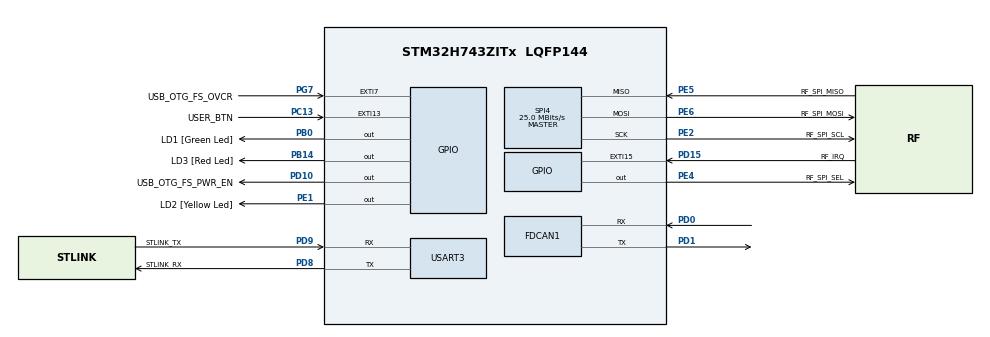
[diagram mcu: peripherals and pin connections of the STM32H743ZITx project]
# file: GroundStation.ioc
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Dma.Request0=USART3_RX
Dma.Request1=USART3_TX
Dma.USART3_RX.0.Direction=DMA_PERIPH_TO_MEMORY
Dma.USART3_RX.0.EventEnable=DISABLE
Dma.USART3_RX.0.FIFOMode=DMA_FIFOMODE_DISABLE
Dma.USART3_RX.0.Instance=DMA1_Stream0
Dma.USART3_RX.0.MemDataAlignment=DMA_MDATAALIGN_BYTE
Dma.USART3_RX.0.MemInc=DMA_MINC_ENABLE
Dma.USART3_RX.0.Mode=DMA_NORMAL
Dma.USART3_RX.0.PeriphDataAlignment=DMA_PDATAALIGN_BYTE
Dma.USART3_RX.0.PeriphInc=DMA_PINC_DISABLE
Dma.USART3_RX.0.Polarity=HAL_DMAMUX_REQ_GEN_RISING
Dma.USART3_RX.0.Priority=DMA_PRIORITY_LOW
Dma.USART3_RX.0.RequestNumber=1
Dma.USART3_RX.0.SignalID=NONE
Dma.USART3_RX.0.SyncEnable=DISABLE
Dma.USART3_RX.0.SyncPolarity=HAL_DMAMUX_SYNC_NO_EVENT
Dma.USART3_RX.0.SyncRequestNumber=1
Dma.USART3_RX.0.SyncSignalID=NONE
Dma.USART3_TX.1.Direction=DMA_MEMORY_TO_PERIPH
Dma.USART3_TX.1.EventEnable=DISABLE
Dma.USART3_TX.1.FIFOMode=DMA_FIFOMODE_DISABLE
Dma.USART3_TX.1.Instance=DMA1_Stream1
Dma.USART3_TX.1.MemDataAlignment=DMA_MDATAALIGN_BYTE
Dma.USART3_TX.1.MemInc=DMA_MINC_ENABLE
Dma.USART3_TX.1.Mode=DMA_NORMAL
Dma.USART3_TX.1.PeriphDataAlignment=DMA_PDATAALIGN_BYTE
Dma.USART3_TX.1.PeriphInc=DMA_PINC_DISABLE
Dma.USART3_TX.1.Polarity=HAL_DMAMUX_REQ_GEN_RISING
Dma.USART3_TX.1.Priority=DMA_PRIORITY_LOW
Dma.USART3_TX.1.RequestNumber=1
Dma.USART3_TX.1.SignalID=NONE
Dma.USART3_TX.1.SyncEnable=DISABLE
Dma.USART3_TX.1.SyncPolarity=HAL_DMAMUX_SYNC_NO_EVENT
Dma.USART3_TX.1.SyncRequestNumber=1
Dma.USART3_TX.1.SyncSignalID=NONE
FDCAN1.CalculateBaudRateNominal=1000000
FDCAN1.CalculateTimeBitNominal=1000
FDCAN1.CalculateTimeQuantumNominal=20.0
FDCAN1.DataPrescaler=25
FDCAN1.DataTimeSeg1=2
FDCAN1.ExtFiltersNbr=1
FDCAN1.NominalPrescaler=1
FDCAN1.NominalSyncJumpWidth=13
FDCAN1.NominalTimeSeg1=40
FDCAN1.NominalTimeSeg2=9
FDCAN1.RxFifo0ElmtsNbr=16
FDCAN1.TxFifoQueueElmtsNbr=16
Mcu.Family=STM32H7
Mcu.Name=STM32H743ZITx
Mcu.Package=LQFP144
NVIC.DMA1_Stream0_IRQn=true\:5\:0\:true\:false\:true\:false\:true\:true
NVIC.DMA1_Stream1_IRQn=true\:5\:0\:true\:false\:true\:false\:true\:true
NVIC.EXTI15_10_IRQn=true\:5\:0\:true\:false\:false\:true\:true\:true
NVIC.FDCAN1_IT0_IRQn=true\:5\:0\:true\:false\:true\:true\:true\:true
NVIC.FDCAN1_IT1_IRQn=true\:5\:0\:true\:false\:true\:true\:true\:true
NVIC.PriorityGroup=NVIC_PRIORITYGROUP_4
NVIC.TIM1_UP_IRQn=true\:15\:0\:false\:false\:true\:false\:true\:true
NVIC.TimeBase=TIM1_UP_IRQn
NVIC.TimeBaseIP=TIM1
NVIC.USART3_IRQn=true\:5\:0\:true\:false\:true\:true\:true\:true
PA1.Signal=ETH_REF_CLK
PA11.Signal=USB_OTG_FS_DM
PA12.Signal=USB_OTG_FS_DP
PA2.Signal=ETH_MDIO
PA7.Signal=ETH_CRS_DV
PA8.Signal=USB_OTG_FS_SOF
PA9.Signal=USB_OTG_FS_VBUS
PB0.GPIO_Label=LD1 [Green Led]
PB0.Signal=GPIO_Output
PB13.Signal=ETH_TXD1
PB14.GPIO_Label=LD3 [Red Led]
PB14.Signal=GPIO_Output
PC1.Signal=ETH_MDC
PC13.GPIO_Label=USER_BTN
PC13.Signal=GPXTI13
PC14-OSC32_IN\ (OSC32_IN).Mode=LSE-External-Oscillator
PC14-OSC32_IN\ (OSC32_IN).Signal=RCC_OSC32_IN
PC15-OSC32_OUT\ (OSC32_OUT).Mode=LSE-External-Oscillator
PC15-OSC32_OUT\ (OSC32_OUT).Signal=RCC_OSC32_OUT
PC4.Signal=ETH_RXD0
PC5.Signal=ETH_RXD1
PD0.Mode=FDCAN_Activate
PD0.Signal=FDCAN1_RX
PD1.Mode=FDCAN_Activate
PD1.Signal=FDCAN1_TX
PD10.GPIO_Label=USB_OTG_FS_PWR_EN
PD10.Signal=GPIO_Output
PD15.GPIO_Label=RF_IRQ
PD15.Signal=GPXTI15
PD8.GPIO_Label=STLINK_RX
PD8.Mode=Asynchronous
PD8.Signal=USART3_TX
PD9.GPIO_Label=STLINK_TX
PD9.Mode=Asynchronous
PD9.Signal=USART3_RX
PE1.GPIO_Label=LD2 [Yellow Led]
PE1.Signal=GPIO_Output
PE2.GPIO_Label=RF_SPI_SCL
PE2.Mode=Full_Duplex_Master
PE2.Signal=SPI4_SCK
PE4.GPIO_Label=RF_SPI_SEL
PE4.Signal=GPIO_Output
PE5.GPIO_Label=RF_SPI_MISO
PE5.Mode=Full_Duplex_Master
PE5.Signal=SPI4_MISO
PE6.GPIO_Label=RF_SPI_MOSI
PE6.Mode=Full_Duplex_Master
PE6.Signal=SPI4_MOSI
PG11.Signal=ETH_TX_EN
PG13.Signal=ETH_TXD0
PG7.GPIO_Label=USB_OTG_FS_OVCR
PG7.Signal=GPXTI7
PH0-OSC_IN\ (PH0).Mode=HSE-External-Oscillator
PH0-OSC_IN\ (PH0).Signal=RCC_OSC_IN
PH1-OSC_OUT\ (PH1).Mode=HSE-External-Oscillator
PH1-OSC_OUT\ (PH1).Signal=RCC_OSC_OUT
ProjectManager.HeapSize=0x200
ProjectManager.StackSize=0x400
ProjectManager.TargetToolchain=CMake
RCC.ADCFreq_Value=75000000
RCC.APB1Freq_Value=64000000
RCC.APB2Freq_Value=64000000
RCC.APB3Freq_Value=64000000
RCC.APB4Freq_Value=64000000
RCC.CortexFreq_Value=64000000
RCC.DIVM1=1
RCC.DIVM2=1
RCC.DIVN1=18
RCC.DIVN2=18
RCC.DIVQ1=3
RCC.DIVQ2=3
RCC.HCLKFreq_Value=64000000
RCC.HSE_VALUE=8000000
RCC.PLL2FRACN=6144
RCC.PLLFRACN=6144
RCC.PLLSourceVirtual=RCC_PLLSOURCE_HSE
RCC.PWR_Regulator_Voltage_Scale=PWR_REGULATOR_VOLTAGE_SCALE2
RCC.SYSCLKFreq_VALUE=64000000
RCC.Spi45ClockSelection=RCC_SPI45CLKSOURCE_PLL2
RCC.USBFreq_Value=50000000
SPI4.CalculateBaudRate=25.0 MBits/s
SPI4.DataSize=SPI_DATASIZE_8BIT
SPI4.Direction=SPI_DIRECTION_2LINES
SPI4.Mode=SPI_MODE_MASTER
SPI4.VirtualType=VM_MASTER
USART3.VirtualMode-Asynchronous=VM_ASYNC
VP_CRC_VS_CRC.Mode=CRC_Activate
VP_MEMORYMAP_VS_MEMORYMAP.Mode=CurAppReg
VP_SYS_VS_tim1.Mode=TIM1
board=NUCLEO-H743ZI2

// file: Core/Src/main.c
/* USER CODE BEGIN Header */
/**
  ******************************************************************************
  * @file           : main.c
  * @brief          : Main program body
  ******************************************************************************
  * @attention
  *
  * Copyright (c) 2024 STMicroelectronics.
  * All rights reserved.
  *
  * This software is licensed under terms that can be found in the LICENSE file
  * in the root directory of this software component.
  * If no LICENSE file comes with this software, it is provided AS-IS.
  *
  ******************************************************************************
  */
/* USER CODE END Header */
#include "main.h"

CRC_HandleTypeDef hcrc;

FDCAN_HandleTypeDef hfdcan1;

SPI_HandleTypeDef hspi4;

UART_HandleTypeDef huart3;
DMA_HandleTypeDef hdma_usart3_rx;
DMA_HandleTypeDef hdma_usart3_tx;

void SystemClock_Config(void);
static void MX_GPIO_Init(void);
static void MX_DMA_Init(void);
static void MX_SPI4_Init(void);
static void MX_USART3_UART_Init(void);
static void MX_CRC_Init(void);
static void MX_FDCAN1_Init(void);

/* USER CODE BEGIN 0 */
void app_main(void);
/* USER CODE END 0 */

int main(void)
{

  /* MCU Configuration--------------------------------------------------------*/

  /* Reset of all peripherals, Initializes the Flash interface and the Systick. */
  HAL_Init();

  /* Configure the system clock */
  SystemClock_Config();

  /* Initialize all configured peripherals */
  MX_GPIO_Init();
  MX_DMA_Init();
  MX_SPI4_Init();
  MX_USART3_UART_Init();
  MX_CRC_Init();
  MX_FDCAN1_Init();
  /* USER CODE BEGIN 2 */
    app_main();
  /* USER CODE END 2 */

  /* Infinite loop */
  while (1)
  {

  }
}

void SystemClock_Config(void)
{
  RCC_OscInitTypeDef RCC_OscInitStruct = {0};
  RCC_ClkInitTypeDef RCC_ClkInitStruct = {0};

  /** Supply configuration update enable
  */
  HAL_PWREx_ConfigSupply(PWR_LDO_SUPPLY);

  /** Configure the main internal regulator output voltage
  */
  __HAL_PWR_VOLTAGESCALING_CONFIG(PWR_REGULATOR_VOLTAGE_SCALE2);

  while(!__HAL_PWR_GET_FLAG(PWR_FLAG_VOSRDY)) {}

  /** Initializes the RCC Oscillators according to the specified parameters
  * in the RCC_OscInitTypeDef structure.
  */
  RCC_OscInitStruct.OscillatorType = RCC_OSCILLATORTYPE_HSI|RCC_OSCILLATORTYPE_HSE;
  RCC_OscInitStruct.HSEState = RCC_HSE_ON;
  RCC_OscInitStruct.HSIState = RCC_HSI_DIV1;
  RCC_OscInitStruct.HSICalibrationValue = RCC_HSICALIBRATION_DEFAULT;
  RCC_OscInitStruct.PLL.PLLState = RCC_PLL_ON;
  RCC_OscInitStruct.PLL.PLLSource = RCC_PLLSOURCE_HSE;
  RCC_OscInitStruct.PLL.PLLM = 1;
  RCC_OscInitStruct.PLL.PLLN = 18;
  RCC_OscInitStruct.PLL.PLLP = 2;
  RCC_OscInitStruct.PLL.PLLQ = 3;
  RCC_OscInitStruct.PLL.PLLR = 2;
  RCC_OscInitStruct.PLL.PLLRGE = RCC_PLL1VCIRANGE_3;
  RCC_OscInitStruct.PLL.PLLVCOSEL = RCC_PLL1VCOMEDIUM;
  RCC_OscInitStruct.PLL.PLLFRACN = 6144;
  if (HAL_RCC_OscConfig(&RCC_OscInitStruct) != HAL_OK)
  {
    Error_Handler();
  }

  /** Initializes the CPU, AHB and APB buses clocks
  */
  RCC_ClkInitStruct.ClockType = RCC_CLOCKTYPE_HCLK|RCC_CLOCKTYPE_SYSCLK
                              |RCC_CLOCKTYPE_PCLK1|RCC_CLOCKTYPE_PCLK2
                              |RCC_CLOCKTYPE_D3PCLK1|RCC_CLOCKTYPE_D1PCLK1;
  RCC_ClkInitStruct.SYSCLKSource = RCC_SYSCLKSOURCE_HSI;
  RCC_ClkInitStruct.SYSCLKDivider = RCC_SYSCLK_DIV1;
  RCC_ClkInitStruct.AHBCLKDivider = RCC_HCLK_DIV1;
  RCC_ClkInitStruct.APB3CLKDivider = RCC_APB3_DIV1;
  RCC_ClkInitStruct.APB1CLKDivider = RCC_APB1_DIV1;
  RCC_ClkInitStruct.APB2CLKDivider = RCC_APB2_DIV1;
  RCC_ClkInitStruct.APB4CLKDivider = RCC_APB4_DIV1;

  if (HAL_RCC_ClockConfig(&RCC_ClkInitStruct, FLASH_LATENCY_1) != HAL_OK)
  {
    Error_Handler();
  }
}

static void MX_CRC_Init(void)
{

  hcrc.Instance = CRC;
  hcrc.Init.DefaultPolynomialUse = DEFAULT_POLYNOMIAL_ENABLE;
  hcrc.Init.DefaultInitValueUse = DEFAULT_INIT_VALUE_ENABLE;
  hcrc.Init.InputDataInversionMode = CRC_INPUTDATA_INVERSION_NONE;
  hcrc.Init.OutputDataInversionMode = CRC_OUTPUTDATA_INVERSION_DISABLE;
  hcrc.InputDataFormat = CRC_INPUTDATA_FORMAT_BYTES;
  if (HAL_CRC_Init(&hcrc) != HAL_OK)
  {
    Error_Handler();
  }

}

static void MX_FDCAN1_Init(void)
{

  hfdcan1.Instance = FDCAN1;
  hfdcan1.Init.FrameFormat = FDCAN_FRAME_CLASSIC;
  hfdcan1.Init.Mode = FDCAN_MODE_NORMAL;
  hfdcan1.Init.AutoRetransmission = DISABLE;
  hfdcan1.Init.TransmitPause = DISABLE;
  hfdcan1.Init.ProtocolException = DISABLE;
  hfdcan1.Init.NominalPrescaler = 1;
  hfdcan1.Init.NominalSyncJumpWidth = 13;
  hfdcan1.Init.NominalTimeSeg1 = 40;
  hfdcan1.Init.NominalTimeSeg2 = 9;
  hfdcan1.Init.DataPrescaler = 25;
  hfdcan1.Init.DataSyncJumpWidth = 1;
  hfdcan1.Init.DataTimeSeg1 = 2;
  hfdcan1.Init.DataTimeSeg2 = 1;
  hfdcan1.Init.MessageRAMOffset = 0;
  hfdcan1.Init.StdFiltersNbr = 0;
  hfdcan1.Init.ExtFiltersNbr = 1;
  hfdcan1.Init.RxFifo0ElmtsNbr = 16;
  hfdcan1.Init.RxFifo0ElmtSize = FDCAN_DATA_BYTES_8;
  hfdcan1.Init.RxFifo1ElmtsNbr = 0;
  hfdcan1.Init.RxFifo1ElmtSize = FDCAN_DATA_BYTES_8;
  hfdcan1.Init.RxBuffersNbr = 0;
  hfdcan1.Init.RxBufferSize = FDCAN_DATA_BYTES_8;
  hfdcan1.Init.TxEventsNbr = 0;
  hfdcan1.Init.TxBuffersNbr = 0;
  hfdcan1.Init.TxFifoQueueElmtsNbr = 16;
  hfdcan1.Init.TxFifoQueueMode = FDCAN_TX_FIFO_OPERATION;
  hfdcan1.Init.TxElmtSize = FDCAN_DATA_BYTES_8;
  if (HAL_FDCAN_Init(&hfdcan1) != HAL_OK)
  {
    Error_Handler();
  }

}

static void MX_SPI4_Init(void)
{

  /* SPI4 parameter configuration*/
  hspi4.Instance = SPI4;
  hspi4.Init.Mode = SPI_MODE_MASTER;
  hspi4.Init.Direction = SPI_DIRECTION_2LINES;
  hspi4.Init.DataSize = SPI_DATASIZE_8BIT;
  hspi4.Init.CLKPolarity = SPI_POLARITY_LOW;
  hspi4.Init.CLKPhase = SPI_PHASE_1EDGE;
  hspi4.Init.NSS = SPI_NSS_SOFT;
  hspi4.Init.BaudRatePrescaler = SPI_BAUDRATEPRESCALER_2;
  hspi4.Init.FirstBit = SPI_FIRSTBIT_MSB;
  hspi4.Init.TIMode = SPI_TIMODE_DISABLE;
  hspi4.Init.CRCCalculation = SPI_CRCCALCULATION_DISABLE;
  hspi4.Init.CRCPolynomial = 0x0;
  hspi4.Init.NSSPMode = SPI_NSS_PULSE_ENABLE;
  hspi4.Init.NSSPolarity = SPI_NSS_POLARITY_LOW;
  hspi4.Init.FifoThreshold = SPI_FIFO_THRESHOLD_01DATA;
  hspi4.Init.TxCRCInitializationPattern = SPI_CRC_INITIALIZATION_ALL_ZERO_PATTERN;
  hspi4.Init.RxCRCInitializationPattern = SPI_CRC_INITIALIZATION_ALL_ZERO_PATTERN;
  hspi4.Init.MasterSSIdleness = SPI_MASTER_SS_IDLENESS_00CYCLE;
  hspi4.Init.MasterInterDataIdleness = SPI_MASTER_INTERDATA_IDLENESS_00CYCLE;
  hspi4.Init.MasterReceiverAutoSusp = SPI_MASTER_RX_AUTOSUSP_DISABLE;
  hspi4.Init.MasterKeepIOState = SPI_MASTER_KEEP_IO_STATE_DISABLE;
  hspi4.Init.IOSwap = SPI_IO_SWAP_DISABLE;
  if (HAL_SPI_Init(&hspi4) != HAL_OK)
  {
    Error_Handler();
  }

}

static void MX_USART3_UART_Init(void)
{

  huart3.Instance = USART3;
  huart3.Init.BaudRate = 115200;
  huart3.Init.WordLength = UART_WORDLENGTH_8B;
  huart3.Init.StopBits = UART_STOPBITS_1;
  huart3.Init.Parity = UART_PARITY_NONE;
  huart3.Init.Mode = UART_MODE_TX_RX;
  huart3.Init.HwFlowCtl = UART_HWCONTROL_NONE;
  huart3.Init.OverSampling = UART_OVERSAMPLING_16;
  huart3.Init.OneBitSampling = UART_ONE_BIT_SAMPLE_DISABLE;
  huart3.Init.ClockPrescaler = UART_PRESCALER_DIV1;
  huart3.AdvancedInit.AdvFeatureInit = UART_ADVFEATURE_NO_INIT;
  if (HAL_UART_Init(&huart3) != HAL_OK)
  {
    Error_Handler();
  }
  if (HAL_UARTEx_SetTxFifoThreshold(&huart3, UART_TXFIFO_THRESHOLD_1_8) != HAL_OK)
  {
    Error_Handler();
  }
  if (HAL_UARTEx_SetRxFifoThreshold(&huart3, UART_RXFIFO_THRESHOLD_1_8) != HAL_OK)
  {
    Error_Handler();
  }
  if (HAL_UARTEx_DisableFifoMode(&huart3) != HAL_OK)
  {
    Error_Handler();
  }

}

static void MX_DMA_Init(void)
{

  /* DMA controller clock enable */
  __HAL_RCC_DMA1_CLK_ENABLE();

  /* DMA interrupt init */
  /* DMA1_Stream0_IRQn interrupt configuration */
  HAL_NVIC_SetPriority(DMA1_Stream0_IRQn, 5, 0);
  HAL_NVIC_EnableIRQ(DMA1_Stream0_IRQn);
  /* DMA1_Stream1_IRQn interrupt configuration */
  HAL_NVIC_SetPriority(DMA1_Stream1_IRQn, 5, 0);
  HAL_NVIC_EnableIRQ(DMA1_Stream1_IRQn);

}

static void MX_GPIO_Init(void)
{
  GPIO_InitTypeDef GPIO_InitStruct = {0};

  /* GPIO Ports Clock Enable */
  __HAL_RCC_GPIOE_CLK_ENABLE();
  __HAL_RCC_GPIOC_CLK_ENABLE();
  __HAL_RCC_GPIOH_CLK_ENABLE();
  __HAL_RCC_GPIOA_CLK_ENABLE();
  __HAL_RCC_GPIOB_CLK_ENABLE();
  __HAL_RCC_GPIOD_CLK_ENABLE();
  __HAL_RCC_GPIOG_CLK_ENABLE();

  /*Configure GPIO pin Output Level */
  HAL_GPIO_WritePin(GPIOE, RF_SPI_SEL_Pin|LD2_Pin, GPIO_PIN_RESET);

  /*Configure GPIO pin Output Level */
  HAL_GPIO_WritePin(GPIOB, LD1_Pin|LD3_Pin, GPIO_PIN_RESET);

  /*Configure GPIO pin Output Level */
  HAL_GPIO_WritePin(USB_OTG_FS_PWR_EN_GPIO_Port, USB_OTG_FS_PWR_EN_Pin, GPIO_PIN_RESET);

  /*Configure GPIO pins : RF_SPI_SEL_Pin LD2_Pin */
  GPIO_InitStruct.Pin = RF_SPI_SEL_Pin|LD2_Pin;
  GPIO_InitStruct.Mode = GPIO_MODE_OUTPUT_PP;
  GPIO_InitStruct.Pull = GPIO_NOPULL;
  GPIO_InitStruct.Speed = GPIO_SPEED_FREQ_LOW;
  HAL_GPIO_Init(GPIOE, &GPIO_InitStruct);

  /*Configure GPIO pin : USER_BTN_Pin */
  GPIO_InitStruct.Pin = USER_BTN_Pin;
  GPIO_InitStruct.Mode = GPIO_MODE_IT_RISING;
  GPIO_InitStruct.Pull = GPIO_NOPULL;
  HAL_GPIO_Init(USER_BTN_GPIO_Port, &GPIO_InitStruct);

  /*Configure GPIO pins : PC1 PC4 PC5 */
  GPIO_InitStruct.Pin = GPIO_PIN_1|GPIO_PIN_4|GPIO_PIN_5;
  GPIO_InitStruct.Mode = GPIO_MODE_AF_PP;
  GPIO_InitStruct.Pull = GPIO_NOPULL;
  GPIO_InitStruct.Speed = GPIO_SPEED_FREQ_LOW;
  GPIO_InitStruct.Alternate = GPIO_AF11_ETH;
  HAL_GPIO_Init(GPIOC, &GPIO_InitStruct);

  /*Configure GPIO pins : PA1 PA2 PA7 */
  GPIO_InitStruct.Pin = GPIO_PIN_1|GPIO_PIN_2|GPIO_PIN_7;
  GPIO_InitStruct.Mode = GPIO_MODE_AF_PP;
  GPIO_InitStruct.Pull = GPIO_NOPULL;
  GPIO_InitStruct.Speed = GPIO_SPEED_FREQ_LOW;
  GPIO_InitStruct.Alternate = GPIO_AF11_ETH;
  HAL_GPIO_Init(GPIOA, &GPIO_InitStruct);

  /*Configure GPIO pins : LD1_Pin LD3_Pin */
  GPIO_InitStruct.Pin = LD1_Pin|LD3_Pin;
  GPIO_InitStruct.Mode = GPIO_MODE_OUTPUT_PP;
  GPIO_InitStruct.Pull = GPIO_NOPULL;
  GPIO_InitStruct.Speed = GPIO_SPEED_FREQ_LOW;
  HAL_GPIO_Init(GPIOB, &GPIO_InitStruct);

  /*Configure GPIO pin : PB13 */
  GPIO_InitStruct.Pin = GPIO_PIN_13;
  GPIO_InitStruct.Mode = GPIO_MODE_AF_PP;
  GPIO_InitStruct.Pull = GPIO_NOPULL;
  GPIO_InitStruct.Speed = GPIO_SPEED_FREQ_LOW;
  GPIO_InitStruct.Alternate = GPIO_AF11_ETH;
  HAL_GPIO_Init(GPIOB, &GPIO_InitStruct);

  /*Configure GPIO pin : USB_OTG_FS_PWR_EN_Pin */
  GPIO_InitStruct.Pin = USB_OTG_FS_PWR_EN_Pin;
  GPIO_InitStruct.Mode = GPIO_MODE_OUTPUT_PP;
  GPIO_InitStruct.Pull = GPIO_NOPULL;
  GPIO_InitStruct.Speed = GPIO_SPEED_FREQ_LOW;
  HAL_GPIO_Init(USB_OTG_FS_PWR_EN_GPIO_Port, &GPIO_InitStruct);

  /*Configure GPIO pin : RF_IRQ_Pin */
  GPIO_InitStruct.Pin = RF_IRQ_Pin;
  GPIO_InitStruct.Mode = GPIO_MODE_IT_RISING;
  GPIO_InitStruct.Pull = GPIO_NOPULL;
  HAL_GPIO_Init(RF_IRQ_GPIO_Port, &GPIO_InitStruct);

  /*Configure GPIO pin : USB_OTG_FS_OVCR_Pin */
  GPIO_InitStruct.Pin = USB_OTG_FS_OVCR_Pin;
  GPIO_InitStruct.Mode = GPIO_MODE_IT_RISING;
  GPIO_InitStruct.Pull = GPIO_NOPULL;
  HAL_GPIO_Init(USB_OTG_FS_OVCR_GPIO_Port, &GPIO_InitStruct);

  /*Configure GPIO pins : PA8 PA11 PA12 */
  GPIO_InitStruct.Pin = GPIO_PIN_8|GPIO_PIN_11|GPIO_PIN_12;
  GPIO_InitStruct.Mode = GPIO_MODE_AF_PP;
  GPIO_InitStruct.Pull = GPIO_NOPULL;
  GPIO_InitStruct.Speed = GPIO_SPEED_FREQ_LOW;
  GPIO_InitStruct.Alternate = GPIO_AF10_OTG1_FS;
  HAL_GPIO_Init(GPIOA, &GPIO_InitStruct);

  /*Configure GPIO pins : PG11 PG13 */
  GPIO_InitStruct.Pin = GPIO_PIN_11|GPIO_PIN_13;
  GPIO_InitStruct.Mode = GPIO_MODE_AF_PP;
  GPIO_InitStruct.Pull = GPIO_NOPULL;
  GPIO_InitStruct.Speed = GPIO_SPEED_FREQ_LOW;
  GPIO_InitStruct.Alternate = GPIO_AF11_ETH;
  HAL_GPIO_Init(GPIOG, &GPIO_InitStruct);

  /* EXTI interrupt init*/
  HAL_NVIC_SetPriority(EXTI15_10_IRQn, 5, 0);
  HAL_NVIC_EnableIRQ(EXTI15_10_IRQn);

}

void HAL_TIM_PeriodElapsedCallback(TIM_HandleTypeDef *htim)
{
  if (htim->Instance == TIM1) {
    HAL_IncTick();
  }
}

void Error_Handler(void)
{
  __disable_irq();
  while (1)
  {
  }
}

#ifdef  USE_FULL_ASSERT
/**
  * @brief  Reports the name of the source file and the source line number
  *         where the assert_param error has occurred.
  * @param  file: pointer to the source file name
  * @param  line: assert_param error line source number
  * @retval None
  */
void assert_failed(uint8_t *file, uint32_t line)
{
  /* USER CODE BEGIN 6 */
  /* User can add his own implementation to report the file name and line number,
     e.g.: printf("Wrong parameters value: file %s on line %d\r\n", file, line) */
  /* USER CODE END 6 */
}
#endif /* USE_FULL_ASSERT */
